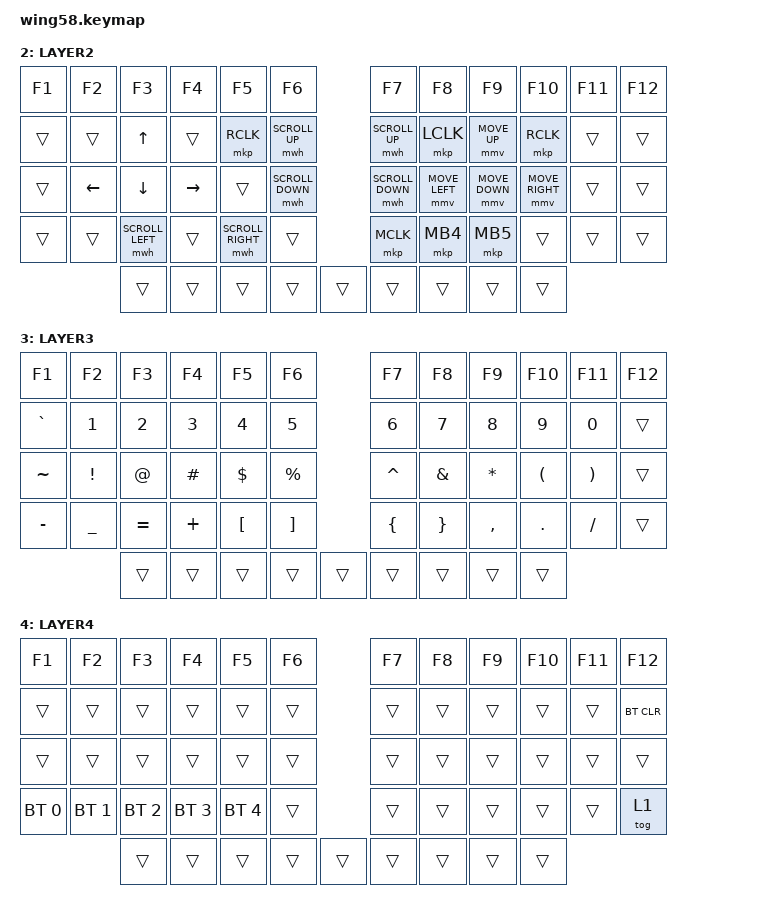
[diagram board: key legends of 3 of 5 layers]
#include <behaviors.dtsi>
#include <dt-bindings/zmk/mouse.h>
#include <dt-bindings/zmk/bt.h>
#include <dt-bindings/zmk/keys.h>

#define DEFAULT 0
#define LAYER1  1
#define LAYER2  2
#define LAYER3  3
#define LAYER4  4
#define LAYER5  5
#define U_MOUSE_MOVE_MAX 1200                     /* <--- New max speed setting (default: 600) */

#undef MOVE_UP
#undef MOVE_DOWN
#undef MOVE_LEFT
#undef MOVE_RIGHT

#define MOVE_UP MOVE_VERT(-U_MOUSE_MOVE_MAX)
#define MOVE_DOWN MOVE_VERT(U_MOUSE_MOVE_MAX)
#define MOVE_LEFT MOVE_HOR(-U_MOUSE_MOVE_MAX)
#define MOVE_RIGHT MOVE_HOR(U_MOUSE_MOVE_MAX)
#define U_MOUSE_SCROLL_MAX 80                    /* <--- New max speed setting (default: 10) */

#undef SCROLL_UP
#undef SCROLL_DOWN
#undef SCROLL_LEFT
#undef SCROLL_RIGHT

#define SCROLL_UP SCROLL_VERT(U_MOUSE_SCROLL_MAX)
#define SCROLL_DOWN SCROLL_VERT(-U_MOUSE_SCROLL_MAX)
#define SCROLL_LEFT SCROLL_HOR(-U_MOUSE_SCROLL_MAX)
#define SCROLL_RIGHT SCROLL_HOR(U_MOUSE_SCROLL_MAX)

&mmv {
    time-to-max-speed-ms = <1000>;
    acceleration-exponent = <1>;
};

&mwh {
    time-to-max-speed-ms = <500>;
    acceleration-exponent = <1>;
};

/ {
    behaviors {
        gqt: global-quick-tap {
            compatible = "zmk,behavior-hold-tap";
            label = "GLOBAL_QUICK_TAP";
            #binding-cells = <2>;
            flavor = "tap-preferred";
            tapping-term-ms = <200>;
            quick-tap-ms = <140>;
            global-quick-tap;
            bindings = <&kp>, <&kp>;
        };

        bhm: balanced_homerow_mods {
            compatible = "zmk,behavior-hold-tap";
            label = "HOMEROW_MODS";
            #binding-cells = <2>;
            tapping-term-ms = <200>;// <---[[moderate duration]]
            quick-tap-ms = <0>;
            flavor = "balanced";
            bindings = <&kp>, <&kp>;
        };

        tdCaps: tap_dance_0 {
            compatible = "zmk,behavior-tap-dance";
            label = "TAP_DANCE_0";
            #binding-cells = <0>;
            tapping-term-ms = <200>;
            bindings = <&kp LSHIFT>, <&kp CAPSLOCK>;
        };
    };

    combos {
        compatible = "zmk,combos";

        capslock {
            bindings = <&kp CAPS>;
            key-positions = <36 47>;
            layers = <0 1>;
        };
    };

    keymap {
        compatible = "zmk,keymap";

        DEFAULT {
            bindings = <
&kp ESC    &kp N1           &kp N2           &kp N3        &kp N4             &kp N5                               &kp N6       &kp N7              &kp N8                &kp N9             &kp N0                    &kp DEL
&kp GRAVE  &kp Q            &kp W            &kp E         &kp R              &kp T                                &kp Y        &kp U               &kp I                 &kp O              &kp P                     &kp BACKSLASH
&kp TAB    &bhm LEFT_GUI A  &bhm LEFT_ALT S  &bhm LCTRL D  &bhm LEFT_SHIFT F  &kp G                                &kp H        &bhm RIGHT_SHIFT J  &bhm RIGHT_CONTROL K  &bhm RIGHT_ALT L   &bhm RIGHT_GUI SEMICOLON  &kp SQT
&kp LSHFT  &kp Z            &kp X            &kp C         &kp V              &kp B                                &kp N        &kp M               &kp COMMA             &kp DOT            &kp FSLH                  &kp RIGHT_SHIFT
                            &kp MINUS        &lt 3 EQUAL   &lt 2 SPACE        &kp ENTER  &kp SPACE  &kp BACKSPACE  &lt 2 SPACE  &lt 4 TAB           &kp LEFT_BRACKET      &kp RIGHT_BRACKET
            >;
        };

        LAYER1 {
            bindings = <
&kp ESC         &kp N1  &kp N2     &kp N3       &kp N4       &kp N5                          &kp N6     &kp N7              &kp N8                &kp N9             &kp N0                    &kp DELETE
&kp GRAVE       &kp Q   &kp W      &kp E        &kp R        &kp T                           &kp Y      &kp U               &kp I                 &kp O              &kp P                     &kp BSLH
&kp TAB         &kp A   &kp S      &kp D        &kp F        &kp G                           &kp H      &bhm RIGHT_SHIFT J  &bhm RIGHT_CONTROL K  &bhm RIGHT_ALT L   &bhm RIGHT_GUI SEMICOLON  &kp SQT
&kp LEFT_SHIFT  &kp Z   &kp X      &kp C        &kp V        &kp B                           &kp N      &kp M               &kp COMMA             &kp DOT            &kp FSLH                  &kp RIGHT_SHIFT
                        &kp MINUS  &lt 3 EQUAL  &lt 2 SPACE  &kp ENTER  &kp SPACE  &kp BSPC  &kp SPACE  &lt 4 TAB           &kp LEFT_BRACKET      &kp RIGHT_BRACKET
            >;
        };

        LAYER2 {
            bindings = <
&kp F1  &kp F2          &kp F3            &kp F4     &kp F5             &kp F6                            &kp F7            &kp F8          &kp F9          &kp F10          &kp F11  &kp F12
&trans  &trans          &kp UP_ARROW      &trans     &mkp RCLK          &mwh SCROLL_UP                    &mwh SCROLL_UP    &mkp LCLK       &mmv MOVE_UP    &mkp RCLK        &trans   &trans
&trans  &kp LEFT_ARROW  &kp DOWN          &kp RIGHT  &trans             &mwh SCROLL_DOWN                  &mwh SCROLL_DOWN  &mmv MOVE_LEFT  &mmv MOVE_DOWN  &mmv MOVE_RIGHT  &trans   &trans
&trans  &trans          &mwh SCROLL_LEFT  &trans     &mwh SCROLL_RIGHT  &trans                            &mkp MCLK         &mkp MB4        &mkp MB5        &trans           &trans   &trans
                        &trans            &trans     &trans             &trans            &trans  &trans  &trans            &trans          &trans
            >;
        };

        LAYER3 {
            bindings = <
&kp F1     &kp F2     &kp F3     &kp F4    &kp F5            &kp F6                             &kp F7          &kp F8           &kp F9     &kp F10               &kp F11                &kp F12
&kp GRAVE  &kp N1     &kp N2     &kp N3    &kp N4            &kp N5                             &kp N6          &kp N7           &kp N8     &kp N9                &kp N0                 &trans
&kp TILDE  &kp EXCL   &kp AT     &kp HASH  &kp DOLLAR        &kp PERCENT                        &kp CARET       &kp AMPERSAND    &kp STAR   &kp LEFT_PARENTHESIS  &kp RIGHT_PARENTHESIS  &trans
&kp MINUS  &kp UNDER  &kp EQUAL  &kp PLUS  &kp LEFT_BRACKET  &kp RIGHT_BRACKET                  &kp LEFT_BRACE  &kp RIGHT_BRACE  &kp COMMA  &kp DOT               &kp SLASH              &trans
                      &trans     &trans    &trans            &trans             &trans  &trans  &trans          &trans           &trans
            >;
        };

        LAYER4 {
            bindings = <
&kp F1        &kp F2        &kp F3        &kp F4        &kp F5        &kp F6                  &kp F7  &kp F8  &kp F9  &kp F10  &kp F11  &kp F12
&trans        &trans        &trans        &trans        &trans        &trans                  &trans  &trans  &trans  &trans   &trans   &bt BT_CLR
&trans        &trans        &trans        &trans        &trans        &trans                  &trans  &trans  &trans  &trans   &trans   &trans
&bt BT_SEL 0  &bt BT_SEL 1  &bt BT_SEL 2  &bt BT_SEL 3  &bt BT_SEL 4  &trans                  &trans  &trans  &trans  &trans   &trans   &tog 1
                            &trans        &trans        &trans        &trans  &trans  &trans  &trans  &trans  &trans
            >;
        };
    };
};
